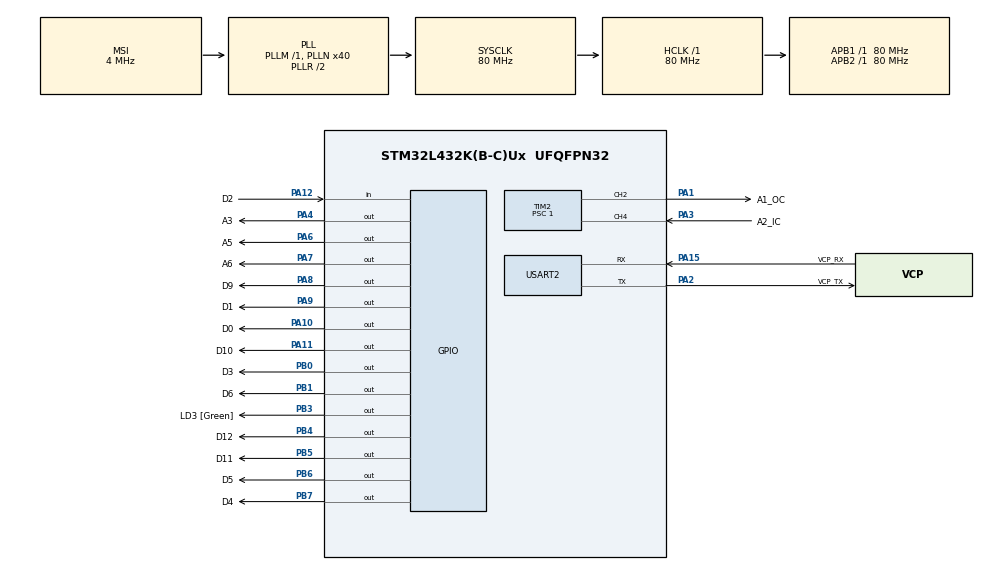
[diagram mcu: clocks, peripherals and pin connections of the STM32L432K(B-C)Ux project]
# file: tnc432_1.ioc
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Mcu.Family=STM32L4
Mcu.Name=STM32L432K(B-C)Ux
Mcu.Package=UFQFPN32
NVIC.PriorityGroup=NVIC_PRIORITYGROUP_4
NVIC.TIM2_IRQn=true\:0\:0\:false\:true\:true\:1\:true\:true
PA0.GPIO_Label=MCO [High speed clock in]
PA0.Mode=HSE-External-Clock-Source-for-LittleOrca
PA0.Signal=RCC_CK_IN
PA1.GPIO_Label=A1_OC
PA1.Signal=S_TIM2_CH2
PA10.GPIO_Label=D0
PA10.Signal=GPIO_Output
PA11.GPIO_Label=D10
PA11.Signal=GPIO_Output
PA12.GPIO_Label=D2
PA12.Signal=GPIO_Input
PA13\ (JTMS-SWDIO).GPIO_Label=SWDIO
PA13\ (JTMS-SWDIO).Mode=Serial_Wire
PA13\ (JTMS-SWDIO).Signal=SYS_JTMS-SWDIO
PA14\ (JTCK-SWCLK).GPIO_Label=SWCLK
PA14\ (JTCK-SWCLK).Mode=Serial_Wire
PA14\ (JTCK-SWCLK).Signal=SYS_JTCK-SWCLK
PA15\ (JTDI).GPIO_Label=VCP_RX
PA15\ (JTDI).Mode=Asynchronous
PA15\ (JTDI).Signal=USART2_RX
PA2.GPIO_Label=VCP_TX
PA2.Mode=Asynchronous
PA2.Signal=USART2_TX
PA3.GPIO_Label=A2_IC
PA3.Signal=S_TIM2_CH4
PA4.GPIO_Label=A3
PA4.Signal=GPIO_Output
PA6.GPIO_Label=A5
PA6.Signal=GPIO_Output
PA7.GPIO_Label=A6
PA7.Signal=GPIO_Output
PA8.GPIO_Label=D9
PA8.Signal=GPIO_Output
PA9.GPIO_Label=D1
PA9.Signal=GPIO_Output
PB0.GPIO_Label=D3
PB0.Signal=GPIO_Output
PB1.GPIO_Label=D6
PB1.Signal=GPIO_Output
PB3\ (JTDO-TRACESWO).GPIO_Label=LD3 [Green]
PB3\ (JTDO-TRACESWO).Signal=GPIO_Output
PB4\ (NJTRST).GPIO_Label=D12
PB4\ (NJTRST).Signal=GPIO_Output
PB5.GPIO_Label=D11
PB5.Signal=GPIO_Output
PB6.GPIO_Label=D5
PB6.Signal=GPIO_Output
PB7.GPIO_Label=D4
PB7.Signal=GPIO_Output
PC14-OSC32_IN\ (PC14).Mode=LSE-External-Oscillator
PC14-OSC32_IN\ (PC14).Signal=RCC_OSC32_IN
PC15-OSC32_OUT\ (PC15).Mode=LSE-External-Oscillator
PC15-OSC32_OUT\ (PC15).Signal=RCC_OSC32_OUT
ProjectManager.HeapSize=0x200
ProjectManager.StackSize=0x400
ProjectManager.TargetToolchain=STM32CubeIDE
RCC.AHBFreq_Value=80000000
RCC.APB1Freq_Value=80000000
RCC.APB1TimFreq_Value=80000000
RCC.APB2Freq_Value=80000000
RCC.APB2TimFreq_Value=80000000
RCC.CortexFreq_Value=80000000
RCC.HCLKFreq_Value=80000000
RCC.HSE_VALUE=8000000
RCC.HSI16_VALUE=16000000
RCC.HSI48_VALUE=48000000
RCC.HSI_VALUE=16000000
RCC.MSI_VALUE=4000000
RCC.PLLMUL=RCC_PLLMUL_4
RCC.PLLN=40
RCC.SYSCLKFreq_VALUE=80000000
RCC.SYSCLKSource=RCC_SYSCLKSOURCE_PLLCLK
RCC.VCOOutputFreq_Value=160000000
SH.S_TIM2_CH2.0=TIM2_CH2,Output Compare2 CH2
SH.S_TIM2_CH4.0=TIM2_CH4,Input_Capture4_from_TI4
SH.S_TIM2_CH4.1=TIM2_CH4,Input_Capture3_from_TI4
TIM2.Channel-Input_Capture3_from_TI4=TIM_CHANNEL_3
TIM2.Channel-Input_Capture4_from_TI4=TIM_CHANNEL_4
TIM2.Channel-Output\ Compare2\ CH2=TIM_CHANNEL_2
TIM2.ICPolarity_CH4=TIM_INPUTCHANNELPOLARITY_BOTHEDGE
TIM2.OCMode_2=TIM_OCMODE_TOGGLE
TIM2.Period=0xffffffff
TIM2.Prescaler=1
USART2.VirtualMode-Asynchronous=VM_ASYNC
board=NUCLEO-L432KC

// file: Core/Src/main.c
/**
  ******************************************************************************
  * @file           : main.c
  * @brief          : Main program body
  ******************************************************************************
  ** This notice applies to any and all portions of this file
  * that are not between comment pairs USER CODE BEGIN and
  * USER CODE END. Other portions of this file, whether
  * inserted by the user or by software development tools
  * are owned by their respective copyright owners.
  *
  * COPYRIGHT(c) 2020 STMicroelectronics
  *
  * Redistribution and use in source and binary forms, with or without modification,
  * are permitted provided that the following conditions are met:
  *   1. Redistributions of source code must retain the above copyright notice,
  *      this list of conditions and the following disclaimer.
  *   2. Redistributions in binary form must reproduce the above copyright notice,
  *      this list of conditions and the following disclaimer in the documentation
  *      and/or other materials provided with the distribution.
  *   3. Neither the name of STMicroelectronics nor the names of its contributors
  *      may be used to endorse or promote products derived from this software
  *      without specific prior written permission.
  *
  * THIS SOFTWARE IS PROVIDED BY THE COPYRIGHT HOLDERS AND CONTRIBUTORS "AS IS"
  * AND ANY EXPRESS OR IMPLIED WARRANTIES, INCLUDING, BUT NOT LIMITED TO, THE
  * IMPLIED WARRANTIES OF MERCHANTABILITY AND FITNESS FOR A PARTICULAR PURPOSE ARE
  * DISCLAIMED. IN NO EVENT SHALL THE COPYRIGHT HOLDER OR CONTRIBUTORS BE LIABLE
  * FOR ANY DIRECT, INDIRECT, INCIDENTAL, SPECIAL, EXEMPLARY, OR CONSEQUENTIAL
  * DAMAGES (INCLUDING, BUT NOT LIMITED TO, PROCUREMENT OF SUBSTITUTE GOODS OR
  * SERVICES; LOSS OF USE, DATA, OR PROFITS; OR BUSINESS INTERRUPTION) HOWEVER
  * CAUSED AND ON ANY THEORY OF LIABILITY, WHETHER IN CONTRACT, STRICT LIABILITY,
  * OR TORT (INCLUDING NEGLIGENCE OR OTHERWISE) ARISING IN ANY WAY OUT OF THE USE
  * OF THIS SOFTWARE, EVEN IF ADVISED OF THE POSSIBILITY OF SUCH DAMAGE.
  *
  ******************************************************************************
  */
#include "main.h"
#include "stm32l4xx_hal.h"
#include "tim.h"
#include "usart.h"
#include "gpio.h"

/* USER CODE BEGIN PV */
/* Private variables ---------------------------------------------------------*/

/* USER CODE END PV */

void SystemClock_Config(void);
static void MX_NVIC_Init(void);

/* USER CODE BEGIN PFP */
/* Private function prototypes -----------------------------------------------*/

/* USER CODE END PFP */

int main(void)
{

  /* MCU Configuration----------------------------------------------------------*/

  /* Reset of all peripherals, Initializes the Flash interface and the Systick. */
  HAL_Init();

  /* Configure the system clock */
  SystemClock_Config();

  /* Initialize all configured peripherals */
  MX_GPIO_Init();
  MX_USART2_UART_Init();
  MX_TIM2_Init();

  /* Initialize interrupts */
  MX_NVIC_Init();
  /* USER CODE BEGIN 2 */

	HAL_TIM_IC_Start_IT(&htim2, TIM_CHANNEL_4);		// start input capture on channel 4 in interrupt mode(on the STM32Nucleo-L432KC, this is PA3, which is mapped to the pin labeled A2)
	HAL_TIM_OC_Start_IT(&htim2, TIM_CHANNEL_2);		// start output compare on channel 2 in interrupt mode (on the STM32Nucleo-L432KC, this is PA1, which is mapped to the pin labeled A1)

	uint32_t blink_timer = 0;
  /* USER CODE END 2 */

  /* Infinite loop */
  /* USER CODE BEGIN WHILE */
	while (1)
	{

		if ((HAL_GetTick() - blink_timer) > 500)
		{
			blink_timer = HAL_GetTick();
			HAL_GPIO_TogglePin(LD3_GPIO_Port, LD3_Pin);		// blink LED to indicate that we are still alive
		}

		HAL_Delay(1);
		char array[100];
		sprintf(array, "Beginning AFSK transmission\n");
		HAL_UART_Transmit(&huart2, array, strlen(array), 10);

		//return false;

  /* USER CODE END WHILE */

	}

}

void SystemClock_Config(void)
{

  RCC_OscInitTypeDef RCC_OscInitStruct;
  RCC_ClkInitTypeDef RCC_ClkInitStruct;
  RCC_PeriphCLKInitTypeDef PeriphClkInit;

    /**Configure LSE Drive Capability
    */
  HAL_PWR_EnableBkUpAccess();

  __HAL_RCC_LSEDRIVE_CONFIG(RCC_LSEDRIVE_LOW);

    /**Initializes the CPU, AHB and APB busses clocks
    */
  RCC_OscInitStruct.OscillatorType = RCC_OSCILLATORTYPE_LSE|RCC_OSCILLATORTYPE_MSI;
  RCC_OscInitStruct.LSEState = RCC_LSE_ON;
  RCC_OscInitStruct.MSIState = RCC_MSI_ON;
  RCC_OscInitStruct.MSICalibrationValue = 0;
  RCC_OscInitStruct.MSIClockRange = RCC_MSIRANGE_6;
  RCC_OscInitStruct.PLL.PLLState = RCC_PLL_ON;
  RCC_OscInitStruct.PLL.PLLSource = RCC_PLLSOURCE_MSI;
  RCC_OscInitStruct.PLL.PLLM = 1;
  RCC_OscInitStruct.PLL.PLLN = 40;
  RCC_OscInitStruct.PLL.PLLP = RCC_PLLP_DIV7;
  RCC_OscInitStruct.PLL.PLLQ = RCC_PLLQ_DIV2;
  RCC_OscInitStruct.PLL.PLLR = RCC_PLLR_DIV2;
  if (HAL_RCC_OscConfig(&RCC_OscInitStruct) != HAL_OK)
  {
    _Error_Handler(__FILE__, __LINE__);
  }

    /**Initializes the CPU, AHB and APB busses clocks
    */
  RCC_ClkInitStruct.ClockType = RCC_CLOCKTYPE_HCLK|RCC_CLOCKTYPE_SYSCLK
                              |RCC_CLOCKTYPE_PCLK1|RCC_CLOCKTYPE_PCLK2;
  RCC_ClkInitStruct.SYSCLKSource = RCC_SYSCLKSOURCE_PLLCLK;
  RCC_ClkInitStruct.AHBCLKDivider = RCC_SYSCLK_DIV1;
  RCC_ClkInitStruct.APB1CLKDivider = RCC_HCLK_DIV1;
  RCC_ClkInitStruct.APB2CLKDivider = RCC_HCLK_DIV1;

  if (HAL_RCC_ClockConfig(&RCC_ClkInitStruct, FLASH_LATENCY_4) != HAL_OK)
  {
    _Error_Handler(__FILE__, __LINE__);
  }

  PeriphClkInit.PeriphClockSelection = RCC_PERIPHCLK_USART2;
  PeriphClkInit.Usart2ClockSelection = RCC_USART2CLKSOURCE_PCLK1;
  if (HAL_RCCEx_PeriphCLKConfig(&PeriphClkInit) != HAL_OK)
  {
    _Error_Handler(__FILE__, __LINE__);
  }

    /**Configure the main internal regulator output voltage
    */
  if (HAL_PWREx_ControlVoltageScaling(PWR_REGULATOR_VOLTAGE_SCALE1) != HAL_OK)
  {
    _Error_Handler(__FILE__, __LINE__);
  }

    /**Configure the Systick interrupt time
    */
  HAL_SYSTICK_Config(HAL_RCC_GetHCLKFreq()/1000);

    /**Configure the Systick
    */
  HAL_SYSTICK_CLKSourceConfig(SYSTICK_CLKSOURCE_HCLK);

    /**Enable MSI Auto calibration
    */
  HAL_RCCEx_EnableMSIPLLMode();

  /* SysTick_IRQn interrupt configuration */
  HAL_NVIC_SetPriority(SysTick_IRQn, 0, 0);
}

/**
  * @brief NVIC Configuration.
  * @retval None
  */
static void MX_NVIC_Init(void)
{
  /* TIM2_IRQn interrupt configuration */
  HAL_NVIC_SetPriority(TIM2_IRQn, 0, 0);
  HAL_NVIC_EnableIRQ(TIM2_IRQn);
}

void _Error_Handler(char *file, int line)
{
	while(1)
	{
	}
}

/************************ (C) COPYRIGHT STMicroelectronics *****END OF FILE****/
